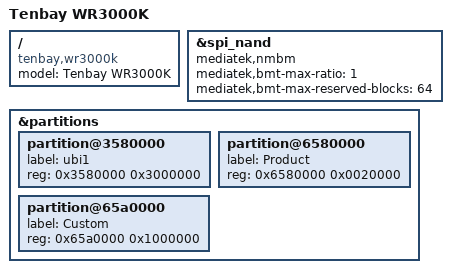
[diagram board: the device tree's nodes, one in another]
// SPDX-License-Identifier: (GPL-2.0 OR MIT)

/dts-v1/;
#include "mt7981b-tenbay-wr3000k-common.dtsi"

/ {
	model = "Tenbay WR3000K";
	compatible = "tenbay,wr3000k", "mediatek,mt7981";
};

&spi_nand {
	mediatek,nmbm;
	mediatek,bmt-max-ratio = <1>;
	mediatek,bmt-max-reserved-blocks = <64>;
};

&partitions {
	partition@3580000 {
		label = "ubi1";
		reg = <0x3580000 0x3000000>;
	};

	partition@6580000 {
		label = "Product";
		reg = <0x6580000 0x0020000>;  // 128 KB
	};

	partition@65a0000 {
		label = "Custom";
		reg = <0x65a0000 0x1000000>;  // 16 MB
	};
};
